# DA1470x register map
Vendor: Dialog; Series: DA1470x; File version: 1.2
CPU: CM33 r0p2, little endian, MPU, FPU, DSP, VTOR, 4 interrupt priority bits
Registers are 32-bit, read-write, reset 0x0 unless marked. A register's access mark holds for its fields unless they carry their own. Offsets are from the block's base; [hi:lo] are bit positions.

## DCACHE — DCACHE registers
Base 0x30100000
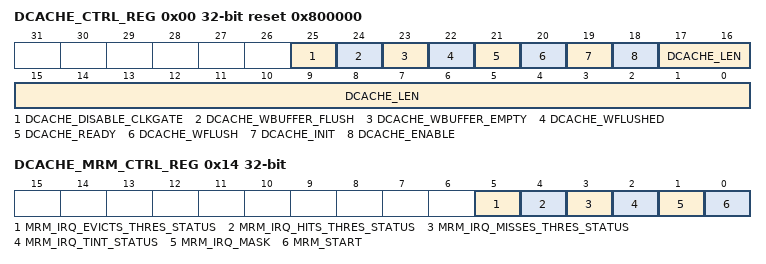
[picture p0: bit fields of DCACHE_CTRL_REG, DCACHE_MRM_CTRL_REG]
0x00 DCACHE_CTRL_REG reset 0x800000 — Dcache Control register
  [25] DCACHE_DISABLE_CLKGATE — Disable the clockgating for the DCACHE 0: Enable clockgating (default) 1: Disable clockgating
  [24] DCACHE_WBUFFER_FLUSH — Write buffer flush 0: Write buffer isn't flushed (default) 1: Write buffer is flushed
  [23] DCACHE_WBUFFER_EMPTY ro — Status of the write buffer 0: Write buffer isn't empty 1: Write buffer is empty
  [22] DCACHE_WFLUSHED — 0: DCACHE is not write flushed yet. 1: DCACHE is write flushed. Note 1: Setting and clearing of this (status) bit field is automatically done by the hardware. Note 2: The CACHE_WFLUSHED bit can also be cleared first by the software by writing a '0'
  [21] DCACHE_READY ro — 0: DCACHE isn't initialized yet 1: DCACHE initialization has been completed
  [20] DCACHE_WFLUSH wo — Write a '1' to this field will trigger a write flush of the 'dirty' lines. All modified data in 'dirty' line will be written back to the PSRAM. The corresponding 'dirty' bits will be cleared. Reading this bit will return '0'
  [19] DCACHE_INIT wo — Write a '1' to this field will trigger an initialization of the cache ('0's are written in the TAG area).. Reading from this field will always return '0'
  [18] DCACHE_ENABLE — Enable the dcache controller HW block: 0: Disabled, all AHB accesses towards the QSPI are bypassing the HW block straight into the PSRAM 1: Enabled, all AHB access towards the QSPI within the cacheable region are cached.
  [17:0] DCACHE_LEN — Length of PSRAM cacheable memory N*1kByte. N = 0 to 131072 (max. of 128 MByte). Setting DCACHE_LEN=0 disables the caching.
0x04 DCACHE_BASE_ADDR_REG — Dcache base address for cacheable region
  [16:0] DCACHE_BASE_ADDR — Base of PSRAM cacheable memory N*1kByte. N = 0 to 131072 (max. of 128 MByte).
0x08 DCACHE_MRM_HITS_REG (reset mask 0x7FFFFFFF) — Dcache MRM (Miss Rate Monitor) HITS register
  [31:0] MRM_HITS — Contains the amount of cache hits.
0x0C DCACHE_MRM_MISSES_REG (reset mask 0x7FFFFFFF) — Dcache MRM (Miss Rate Monitor) MISSES register
  [31:0] MRM_MISSES — Contains the amount of cache misses.
0x10 DCACHE_MRM_EVICTS_REG (reset mask 0x7FFFFFFF) — Dcache MRM (Miss Rate Monitor) EVICTS register
  [31:0] MRM_EVICTS — Contains the amount of cache evicts
0x14 DCACHE_MRM_CTRL_REG — Dcache MRM (Miss Rate Monitor) CONTROL register
  [5] MRM_IRQ_EVICTS_THRES_STATUS — 0: No interrupt is generated. 1: Interrupt (pulse-sensitive) is generated because the number of cache evicts reached the programmed threshold (threshold != 0).
  [4] MRM_IRQ_HITS_THRES_STATUS — 0: No interrupt is generated. 1: Interrupt (pulse-sensitive) is generated because the number of cache hits reached the programmed threshold (threshold != 0).
  [3] MRM_IRQ_MISSES_THRES_STATUS — 0: No interrupt is generated. 1: Interrupt (pulse-sensitive) is generated because the number of cache misses reached the programmed threshold (threshold != 0).
  [2] MRM_IRQ_TINT_STATUS — 0: No interrupt is generated. 1: Interrupt (pulse-sensitive) is generated because the time interval counter reached the end (time interval != 0).
  [1] MRM_IRQ_MASK — 0: Disables interrupt generation. 1: Enables interrupt generation. Note: The Cache MRM generates a pulse-sensitive interrupt towards the ARM processor,
  [0] MRM_START — 0: Freeze the "misses/hits" counters and reset the time interval counter to the programmed value in CACHE_MRM_TINT_REG. 1: Enables the counters. Note: In case CACHE_MRM_CTRL_REG[MRM_START] is set to '1' and CACHE_MRM_TINT_REG (!=0) is used for the MRM interrupt generation, the time interval counter counts down (on a fixed reference clock of 16 MHz) until it's '0'. At that time CACHE_MRM_CTRL_REG[MRM_START] will be reset automatically to '0' by the MRM hardware and the MRM interrupt will be generated.
0x18 DCACHE_MRM_TINT_REG — Dcache MRM (Miss Rate Monitor) TIME INTERVAL register
  [18:0] MRM_TINT — Defines the time interval for the monitoring in 32 MHz clock cycles. See also the description of CACHE_MRM_CTRL_REG[MRM_IRQ_TINT_STATUS]. Note: When MRM_TINT=0 (unrealistic value), no interrupt will be generated.
0x1C DCACHE_MRM_MISSES_THRES_REG (reset mask 0x7FFFFFFF) — Dcache MRM (Miss Rate Monitor) THRESHOLD register
  [31:0] MRM_MISSES_THRES — Defines the misses threshold to trigger the interrupt generation. See also the description of CACHE_MRM_CTRL_REG[MRM_IRQ_MISSES_THRES_STATUS]. Note: When MRM_MISSES_THRES=0 (unrealistic value), no interrupt will be generated.
0x20 DCACHE_MRM_HITS_THRES_REG (reset mask 0x7FFFFFFF) — Dcache MRM (Miss Rate Monitor) HITS THRESHOLD register
  [31:0] MRM_HITS_THRES — Defines the hits threshold to trigger the interrupt generation. See also the description of CACHE_MRM_CTRL_REG[MRM_IRQ_HITS_THRES_STATUS]. Note: When MRM_HITS_THRES=0 (unrealistic value), no interrupt will be generated.
0x24 DCACHE_MRM_EVICTS_THRES_REG (reset mask 0x7FFFFFFF) — Dcache MRM (Miss Rate Monitor) EVICTS THRESHOLD register
  [31:0] MRM_EVICTS_THRES — Defines the hits threshold to trigger the interrupt generation. See also the description of CACHE_MRM_CTRL_REG[MRM_IRQ_EVICTS_THRES_STATUS]. Note: When MRM_EVICTS_THRES=0 (unrealistic value), no interrupt will be generated.
